# CH32M030 register map
Vendor: WCH Ltd.; File version: 1.1
Registers are 32-bit, read-write, reset 0x0 unless marked. A register's access mark holds for its fields unless they carry their own. Offsets are from the block's base; [hi:lo] are bit positions.

## OPA — OPA_CMP
Base 0x40024800
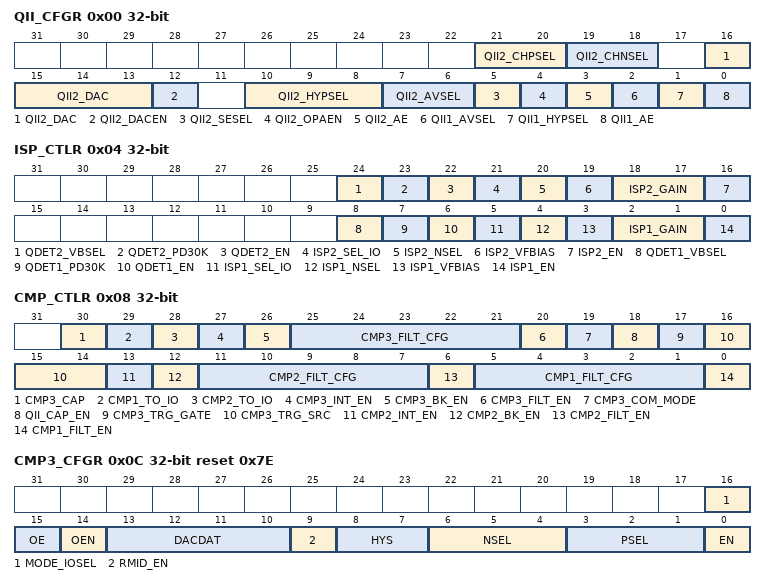
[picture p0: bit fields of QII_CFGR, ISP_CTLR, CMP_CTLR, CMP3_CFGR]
0x00 QII_CFGR — OPA_CMP_QII configuration register
  [21:20] QII2_CHPSEL — Input selection at the positive end of the QII2_CMP
  [19:18] QII2_CHNSEL — Input selection at the negative end of the QII2_CMP
  [16:13] QII2_DAC — QII2_DAC output voltage selection
  [12] QII2_DACEN — QII2_DAC enable
  [10:8] QII2_HYPSEL — QII2_CMP hysteresis selection
  [7:6] QII2_AVSEL — QII2_OPA gain selection
  [5] QII2_SESEL — QII2 single end amplification mode selection
  [4] QII2_OPAEN — QII2_OPA enable
  [3] QII2_AE — QII2_CMP enable
  [2] QII1_AVSEL — QII1_OPA gain selection
  [1] QII1_HYPSEL — QII1_CMP hysteresis selection
  [0] QII1_AE — QII1_CMP enable
0x04 ISP_CTLR — ISP control register
  [24] QDET2_VBSEL — The ISP2 module Q value detects the reference voltage enabled
  [23] QDET2_PD30K — The Q value of the ISP2 module detects the 30K resistance enabled
  [22] QDET2_EN — ISP2 module Q value detection enabled
  [21] ISP2_SEL_IO — The switch ISP2 module outputs to the ADC
  [20] ISP2_NSEL — Input selection at the negative end of the ISP2
  [19] ISP2_VFBIAS — ISP2 module reference voltage selection
  [18:17] ISP2_GAIN — ISP2_OPA gain selection
  [16] ISP2_EN — ISP2 module enable
  [8] QDET1_VBSEL — The ISP1 module Q value detects the reference voltage enabled
  [7] QDET1_PD30K — The Q value of the ISP1 module detects the 30K resistance enabled
  [6] QDET1_EN — ISP1 module Q value detection enabled
  [5] ISP1_SEL_IO — The switch ISP1 module outputs to the ADC
  [4] ISP1_NSEL — Input selection at the negative end of the ISP1
  [3] ISP1_VFBIAS — ISP1 module reference voltage selection
  [2:1] ISP1_GAIN — ISP1_OPA gain selection
  [0] ISP1_EN — ISP1 module enable
0x08 CMP_CTLR — CMP1_2_3 control register
  [30] CMP3_CAP — CMP3 compares the output of the 4 channels internally connected to TIMER2
  [29] CMP1_TO_IO — The CMP1 push-pull output is internally connected to the IO function
  [28] CMP2_TO_IO — The CMP2 push-pull output is internally connected to the IO function
  [27] CMP3_INT_EN — Enable CMP3 output interrupt
  [26] CMP3_BK_EN — Enable CMP3 output connect to timer 1 brake input
  [25:21] CMP3_FILT_CFG — CMP3 output digital filter length configuration
  [20] CMP3_FILT_EN — CMP3 output digital filtering function was enabled
  [19] CMP3_COM_MODE — CMP3 continues comparison mode is enabled
  [18] QII_CAP_EN — The QII output is sent internally directly to the TIM3 capture enable bit
  [17] CMP3_TRG_GATE — CMP3 hardware trigger channel switching
  [16:14] CMP3_TRG_SRC — CMP3 hardware trigger source selection
  [13] CMP2_INT_EN — Enable CMP2 output interrupt
  [12] CMP2_BK_EN — Enable CMP2 output connect to timer 1 brake input
  [11:7] CMP2_FILT_CFG — CMP2 output digital filter length configuration
  [6] CMP2_FILT_EN — CMP2 output digital filtering function was enabled
  [5:1] CMP1_FILT_CFG — CMP1 output digital filter length configuration
  [0] CMP1_FILT_EN — CMP1 output digital filtering function was enabled
0x0C CMP3_CFGR reset 0x7E — CMP3 configur register
  [16] MODE_IOSEL — pin selection when CMP3 push-pull output is connected to IO
  [15] OE — IO output is enabled when CMP3 push-pull output is connected to IO
  [14] OEN — enable CMP3 analog output to IO
  [13:10] DACDAT — CMP3 module DAC output selection
  [9] RMID_EN — CMP3 virtual center point was enabled
  [8:7] HYS — CMP3 hysteresis voltage selection
  [6:4] NSEL — CMP3 nagetive channel selection
  [3:1] PSEL — CMP3 positive channel selection
  [0] EN — CMP3 enable
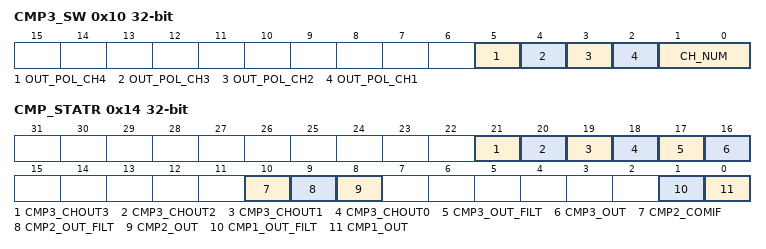
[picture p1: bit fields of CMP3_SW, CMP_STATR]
0x10 CMP3_SW — CMP3 switch register
  [5] OUT_POL_CH4 — the comparison output polarity configuration bit for the channel 4
  [4] OUT_POL_CH3 — the comparison output polarity configuration bit for the third channel
  [3] OUT_POL_CH2 — the comparison output polarity configuration bit for the second channel
  [2] OUT_POL_CH1 — the first channel to compare the output polarity configuration bit
  [1:0] CH_NUM — CMP3 channel number of TIM2 channels to switch
0x14 CMP_STATR access per field — CMP state register
  [21] CMP3_CHOUT3 rw — CMP3 channel switch the comparison output of the third channel
  [20] CMP3_CHOUT2 rw — CMP3 channel switch the comparison output of the second channel
  [19] CMP3_CHOUT1 rw — CMP3 channel switch the comparison output of the first channel
  [18] CMP3_CHOUT0 rw — CMP3 channel switch the comparison output of the channel 0
  [17] CMP3_OUT_FILT ro — Open the output of CMP3 filter
  [16] CMP3_OUT ro — Turn off the output of CMP3 filter
  [10] CMP2_COMIF rw — The CMP2 output is a high level interrupt flag bit
  [9] CMP2_OUT_FILT ro — Open the output of CMP2 filter
  [8] CMP2_OUT ro — Turn off the output of CMP2 filter
  [1] CMP1_OUT_FILT ro — Open the output of CMP1 filter
  [0] CMP1_OUT ro — Turn off the output of CMP1 filter
